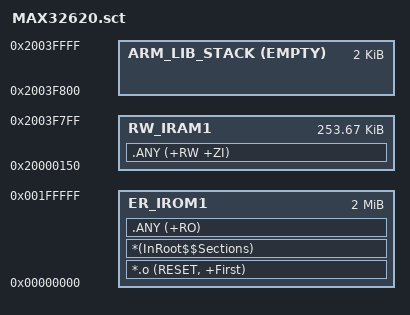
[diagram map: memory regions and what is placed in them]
#! armcc -E
; MAX32620
; 2MB FLASH (0x200000) @ 0x000000000
; 256KB RAM (0x40000) @ 0x20000000



; MAX32620: 2MB FLASH (0x200000) + 256KB RAM (0x40000)

#if !defined(MBED_BOOT_STACK_SIZE)
  #define MBED_BOOT_STACK_SIZE 0x800
#endif

#define Stack_Size MBED_BOOT_STACK_SIZE

LR_IROM1 0x00000000 0x200000  {    ; load region size_region
    ER_IROM1 0x00000000 0x200000  {  ; load address = execution address 
        *.o (RESET, +First)
        *(InRoot$$Sections)
        .ANY (+RO)
    }

    ; [RAM] Vector table dynamic copy: 84 vectors * 4 bytes = 336 (0x150)
    ; for 8 byte alignment
    RW_IRAM1 (0x20000000+0x150) (0x40000-0x150-Stack_Size)  {  ; RW data
        .ANY (+RW +ZI)
    }
    ARM_LIB_STACK (0x20000000+0x40000) EMPTY -Stack_Size { ; stack
    }
}
